# R9A09G057H register map
Vendor: Renesas Electronics; File version: 1.0
Registers are 32-bit, read-write, no defined reset value unless marked. A register's access mark holds for its fields unless they carry their own. Offsets are from the block's base; [hi:lo] are bit positions; lines under a group give offsets from that group; {n}, {i} and the like mark numbered series.

## R_SCU — IO define file for scu.
Base 0x12C10000
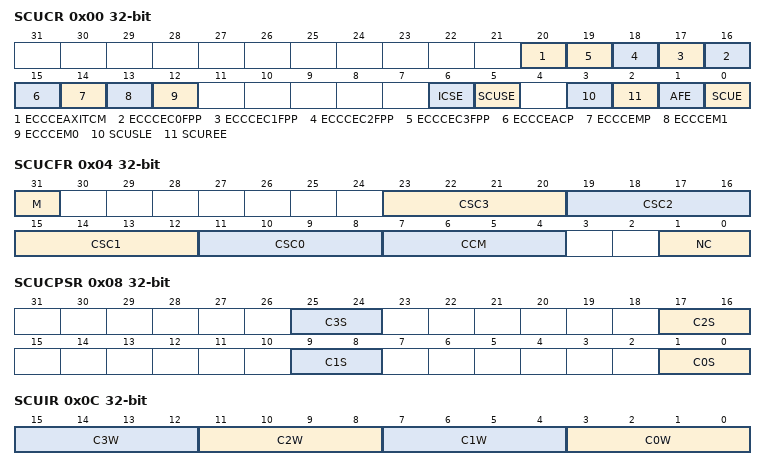
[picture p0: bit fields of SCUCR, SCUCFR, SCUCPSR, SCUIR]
0x00 SCUCR
  [20] ECCCEAXITCM, [n+16] ECCCEC{n}FPP (n=0..3), [15] ECCCEACP, [14] ECCCEMP, [13] ECCCEM1, [12] ECCCEM0, [6] ICSE, [5] SCUSE, [3] SCUSLE, [2] SCUREE, [1] AFE, [0] SCUE
0x04 SCUCFR
  [31] M, [4n+11:4n+8] CSC{n} (n=0..3), [7:4] CCM, [1:0] NC
0x08 SCUCPSR
  [8n+1:8n] C{n}S (n=0..3)
0x0C SCUIR
  [4n+3:4n] C{n}W (n=0..3)
0x40 MFSAR
  [31:20] FSA ro
0x44 MFEAR
  [31:20] FEA ro
0x48 PFSAR
  [31:20] FSA ro
0x4C PFEAR
  [31:20] FEA ro
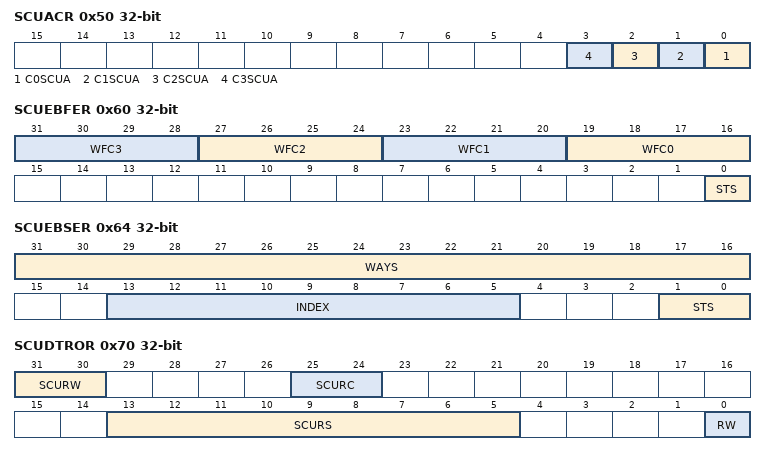
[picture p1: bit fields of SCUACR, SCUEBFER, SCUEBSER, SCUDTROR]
0x50 SCUACR
  [n] C{n}SCUA (n=0..3)
0x60 SCUEBFER
  [4n+19:4n+16] WFC{n} (n=0..3), [0] STS
0x64 SCUEBSER
  [31:16] WAYS, [13:5] INDEX, [1:0] STS
0x70 SCUDTROR
  [31:30] SCURW, [25:24] SCURC, [13:5] SCURS, [0] RW
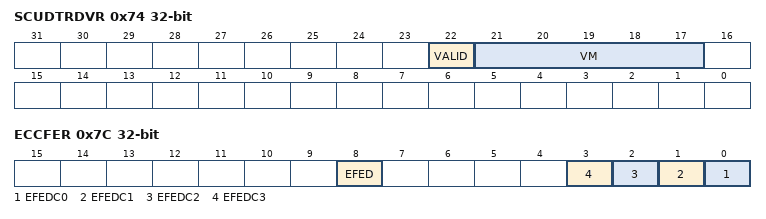
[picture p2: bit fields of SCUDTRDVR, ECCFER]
0x74 SCUDTRDVR
  [22] VALID, [21:17] VM
0x78 SCUDTRECR
  [6:0] CHUNK
0x7C ECCFER
  [8] EFED, [n] EFEDC{n} (n=0..3)
{0x80+8i} FPPFSAR{i} (i=0..3)
  [31:20] FSA
{0x84+8i} FPPFEAR{i} (i=0..3)
  [31:20] FEA

## R_CRC — IO define file for crc.
Base 0x13000800
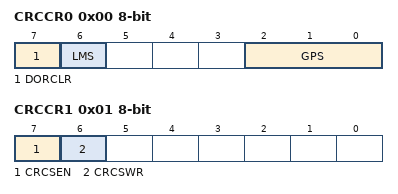
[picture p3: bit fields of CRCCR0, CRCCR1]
0x00 CRCCR0 8-bit
  [7] DORCLR wo, [6] LMS, [2:0] GPS
0x01 CRCCR1 8-bit
  [7] CRCSEN, [6] CRCSWR
0x04 CRCDIR
0x04 CRCDIR_BY 8-bit
0x08 CRCDOR
0x08 CRCDOR_HA 16-bit
0x08 CRCDOR_BY 8-bit
0x0C CRCSAR 16-bit
  [15:0] CRCSA

## R_DMAC_B0 — IO define file for dmac.
Base 0x11400000
Same registers: R_DMAC_B3 0x12000000, R_DMAC_B4 0x12010000, R_DMAC_B1 0x14830000, R_DMAC_B2 0x14840000
{0x0+0x400*i} GRP[{i}] (i=0..1) group — GRP register group
  {0x0+0x40*j} CH[{j}] (j=0..7) group — CH register group
    {0x0+0xC*k} N[{k}] (k=0..1) group — N register group
      0x00 SA
      0x04 DA
      0x08 TB
    0x18 CRSA ro
    0x1C CRDA ro
    0x20 CRTB ro
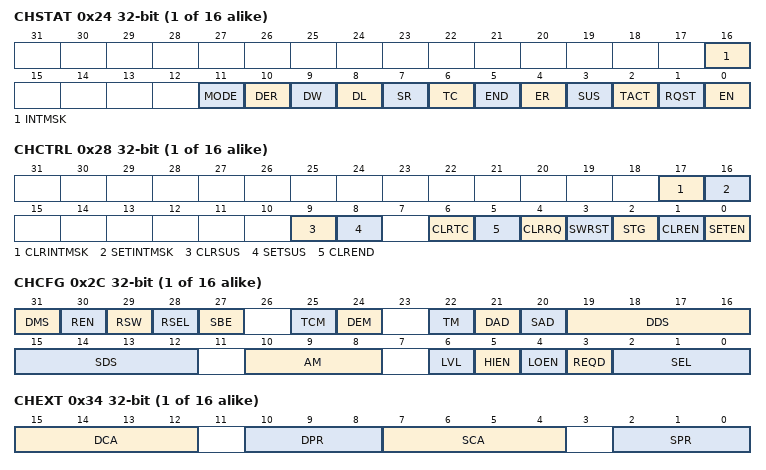
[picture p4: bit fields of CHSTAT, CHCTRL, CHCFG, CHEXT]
    0x24 CHSTAT ro
      [16] INTMSK, [11] MODE, [10] DER, [9] DW, [8] DL, [7] SR, [6] TC, [5] END, [4] ER, [3] SUS, [2] TACT, [1] RQST, [0] EN
    0x28 CHCTRL
      [17] CLRINTMSK, [16] SETINTMSK, [9] CLRSUS, [8] SETSUS, [6] CLRTC, [5] CLREND, [4] CLRRQ, [3] SWRST, [2] STG, [1] CLREN, [0] SETEN
    0x2C CHCFG
      [31] DMS, [30] REN, [29] RSW, [28] RSEL, [27] SBE, [25] TCM, [24] DEM, [22] TM, [21] DAD, [20] SAD, [19:16] DDS, [15:12] SDS, [10:8] AM, [6] LVL, [5] HIEN, [4] LOEN, [3] REQD, [2:0] SEL
    0x30 CHITVL
      [15:0] ITVL
    0x34 CHEXT
      [15:12] DCA, [10:8] DPR, [7:4] SCA, [2:0] SPR
    0x38 NXLA
    0x3C CRLA ro
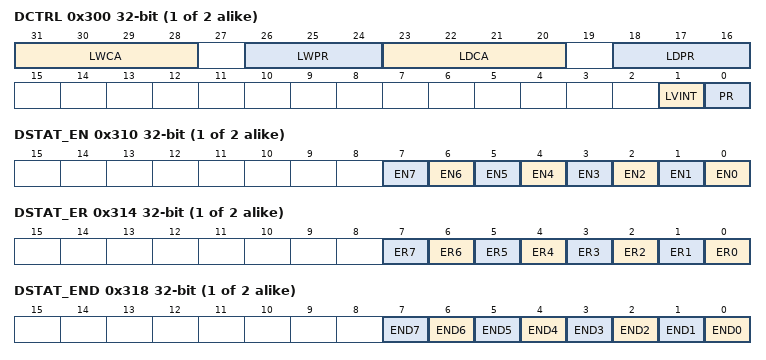
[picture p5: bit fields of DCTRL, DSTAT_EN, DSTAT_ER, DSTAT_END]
  0x300 DCTRL
    [31:28] LWCA, [26:24] LWPR, [23:20] LDCA, [18:16] LDPR, [1] LVINT, [0] PR
  0x310 DSTAT_EN ro
    [n] EN{n} (n=0..7)
  0x314 DSTAT_ER ro
    [n] ER{n} (n=0..7)
  0x318 DSTAT_END ro
    [n] END{n} (n=0..7)
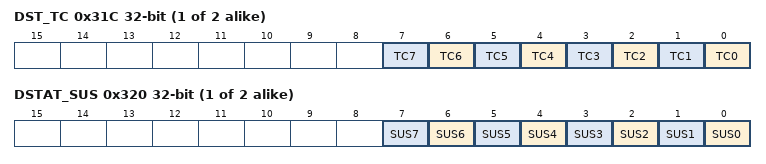
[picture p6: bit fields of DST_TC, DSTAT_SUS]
  0x31C DST_TC ro
    [n] TC{n} (n=0..7)
  0x320 DSTAT_SUS ro
    [n] SUS{n} (n=0..7)

## R_GTM0 — IO define file for gtm.
Base 0x11800000
Same registers: R_GTM1 0x11801000, R_GTM4 0x12C00000, R_GTM5 0x12C01000, R_GTM6 0x12C02000, R_GTM7 0x12C03000, R_GTM2 0x14000000, R_GTM3 0x14001000
0x00 OSTMnCMP
0x04 OSTMnCNT ro
0x10 OSTMnTE 8-bit ro
  [0] OSTMnTE
0x14 OSTMnTS 8-bit
  [0] OSTMnTS wo
0x18 OSTMnTT 8-bit
  [0] OSTMnTT wo
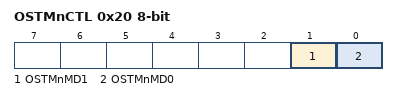
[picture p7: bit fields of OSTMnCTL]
0x20 OSTMnCTL 8-bit
  [1] OSTMnMD1, [0] OSTMnMD0

## R_MHU_NS0 — IO define file for mhu.
Base 0x10480000
Same registers: R_MHU_NS{n} {0x10480000+0x20*n} (n=1..41), R_MHU_S{n} {0x10481000+0x20*n} (n=0..41)
0x00 MSG_INT_STSn ro
  [0] STAT
0x04 MSG_INT_SETn
  [0] SET
0x08 MSG_INT_CLRn
  [0] CLEAR
0x10 RSP_INT_STSn ro
  [0] STAT
0x14 RSP_INT_SETn
  [0] SET
0x18 RSP_INT_CLRn
  [0] CLEAR

## R_MHU_SWINT0 — IO define file for mhu.
Base 0x10480800
Same registers: R_MHU_SWINT{n} {0x10480800+0x10*n} (n=1..27)
0x00 SW_INT_STSn ro
  [0] STAT
0x04 SW_INT_SETn
  [0] SET
0x08 SW_INT_CLRn
  [0] CLEAR

## R_PDM0 — IO define file for pdm.
Base 0x11040000
Same registers: R_PDM1 0x11050000
0x00 PDCSTRTR
  [2:0] STRTRG
0x04 PDCSTPTR
  [2:0] STPTRG
0x08 PDCCHGTR
  [2:0] CHGTRG
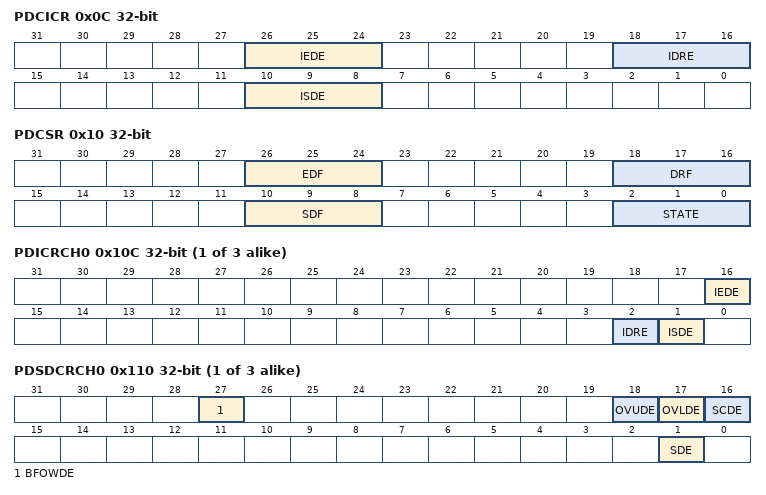
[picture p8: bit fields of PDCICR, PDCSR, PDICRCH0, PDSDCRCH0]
0x0C PDCICR
  [26:24] IEDE, [18:16] IDRE, [10:8] ISDE
0x10 PDCSR ro
  [26:24] EDF, [18:16] DRF, [10:8] SDF, [2:0] STATE
0x14 PDCSCR
  [10:8] SDFC
0x20 PDCSDCR
  [2:0] SDE
0x24 PDCDRCR
  [2:0] DATRE
0x28 PDCDCR
  [2:0] DATC
0x80 PDVR ro
  [11:0] VER
{0x100+0x100*i} PDSTRTRCH{i} (i=0..2)
  [0] STRTRG
{0x104+0x100*i} PDSTPTRCH{i} (i=0..2)
  [0] STPTRG
{0x108+0x100*i} PDCHGTRCH{i} (i=0..2)
  [0] CHGTRG
{0x10C+0x100*i} PDICRCH{i} (i=0..2)
  [16] IEDE, [2] IDRE, [1] ISDE
{0x110+0x100*i} PDSDCRCH{i} (i=0..2)
  [27] BFOWDE, [18] OVUDE, [17] OVLDE, [16] SCDE, [1] SDE
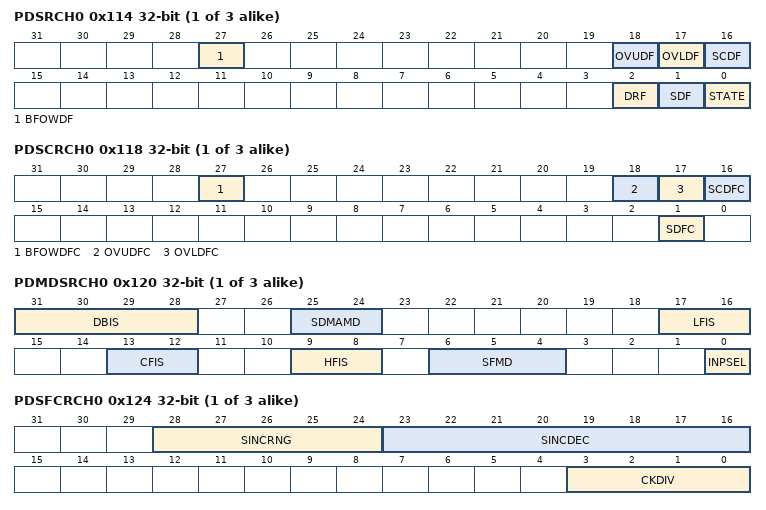
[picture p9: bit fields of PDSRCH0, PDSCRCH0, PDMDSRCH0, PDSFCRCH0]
{0x114+0x100*i} PDSRCH{i} ro (i=0..2)
  [27] BFOWDF, [18] OVUDF, [17] OVLDF, [16] SCDF, [2] DRF, [1] SDF, [0] STATE
{0x118+0x100*i} PDSCRCH{i} (i=0..2)
  [27] BFOWDFC, [18] OVUDFC, [17] OVLDFC, [16] SCDFC, [1] SDFC
{0x120+0x100*i} PDMDSRCH{i} (i=0..2)
  [31:28] DBIS, [25:24] SDMAMD, [17:16] LFIS, [13:12] CFIS, [9:8] HFIS, [6:4] SFMD, [0] INPSEL
{0x124+0x100*i} PDSFCRCH{i} (i=0..2)
  [28:24] SINCRNG, [23:16] SINCDEC, [3:0] CKDIV
{0x128+0x100*i} PDHFCS0RCH{i} (i=0..2)
  [15:0] HFSm
{0x12C+0x100*i} PDHFCK1RCH{i} (i=0..2)
  [15:0] HFKm
{0x130+0x100*i} PDHFCH0RCH{i} (i=0..2)
  [15:0] HFH0
{0x134+0x100*i} PDHFCH1RCH{i} (i=0..2)
  [15:0] HFH1
{0x138+4i} PDCFCH{i:02}RCH0 (i=0..10)
  [12:0] CFH{i:02}
{0x164+0x100*i} PDLFCH010RCH{i} (i=0..2)
  [12:0] LFH010
{0x168+0x100*i} PDLFCH100RCH{i} (i=0..2)
  [12:0] LFH100
{0x16C+0x100*i} PDLFCH101RCH{i} (i=0..2)
  [12:0] LFH101
{0x170+0x100*i} PDLFCH102RCH{i} (i=0..2)
  [12:0] LFH102
{0x174+0x100*i} PDLFCH103RCH{i} (i=0..2)
  [12:0] LFH103
{0x178+0x100*i} PDLFCH104RCH{i} (i=0..2)
  [12:0] LFH104
{0x17C+0x100*i} PDLFCH105RCH{i} (i=0..2)
  [12:0] LFH105
{0x180+0x100*i} PDLFCH106RCH{i} (i=0..2)
  [12:0] LFH106
{0x184+0x100*i} PDLFCH107RCH{i} (i=0..2)
  [12:0] LFH107
{0x188+0x100*i} PDLFCH108RCH{i} (i=0..2)
  [12:0] LFH108
{0x18C+0x100*i} PDLFCH109RCH{i} (i=0..2)
  [12:0] LFH109
{0x190+0x100*i} PDLFCH110RCH{i} (i=0..2)
  [12:0] LFH110
{0x194+0x100*i} PDLFCH111RCH{i} (i=0..2)
  [12:0] LFH111
{0x198+0x100*i} PDLFCH112RCH{i} (i=0..2)
  [12:0] LFH112
{0x19C+0x100*i} PDLFCH113RCH{i} (i=0..2)
  [12:0] LFH113
{0x1A0+0x100*i} PDLFCH114RCH{i} (i=0..2)
  [12:0] LFH114
{0x1A4+0x100*i} PDLFCH115RCH{i} (i=0..2)
  [12:0] LFH115
{0x1A8+0x100*i} PDLFCH116RCH{i} (i=0..2)
  [12:0] LFH116
{0x1AC+0x100*i} PDLFCH117RCH{i} (i=0..2)
  [12:0] LFH117
{0x1B0+0x100*i} PDLFCH118RCH{i} (i=0..2)
  [12:0] LFH118
{0x1B4+0x100*i} PDLFCH119RCH{i} (i=0..2)
  [12:0] LFH119
{0x1B8+0x100*i} PDSDLTRCH{i} (i=0..2)
  [19:0] SDETL
{0x1BC+0x100*i} PDSDUTRCH{i} (i=0..2)
  [19:0] SDETU
{0x1C0+0x100*i} PDDBCRCH{i} (i=0..2)
  [2:0] DATRITHR
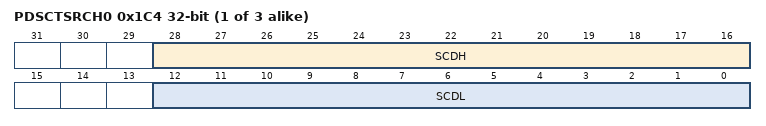
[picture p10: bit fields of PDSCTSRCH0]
{0x1C4+0x100*i} PDSCTSRCH{i} (i=0..2)
  [28:16] SCDH, [12:0] SCDL
{0x1C8+0x100*i} PDOVLTRCH{i} (i=0..2)
  [19:0] OVDL
{0x1CC+0x100*i} PDOVUTRCH{i} (i=0..2)
  [19:0] OVDU
{0x1E0+0x100*i} PDDRCRCH{i} (i=0..2)
  [0] DATRE
{0x1E4+0x100*i} PDDCRCH{i} (i=0..2)
  [0] DATC
{0x1E8+0x100*i} PDDRRCH{i} ro (i=0..2)
  [19:0] DAT
{0x1EC+0x100*i} PDDSRCH{i} ro (i=0..2)
  [7:0] DATNUM
{0x238+4i} PDCFCH{i:02}RCH1 (i=0..10)
  [12:0] CFH{i:02}
{0x338+4i} PDCFCH{i:02}RCH2 (i=0..10)
  [12:0] CFH{i:02}
